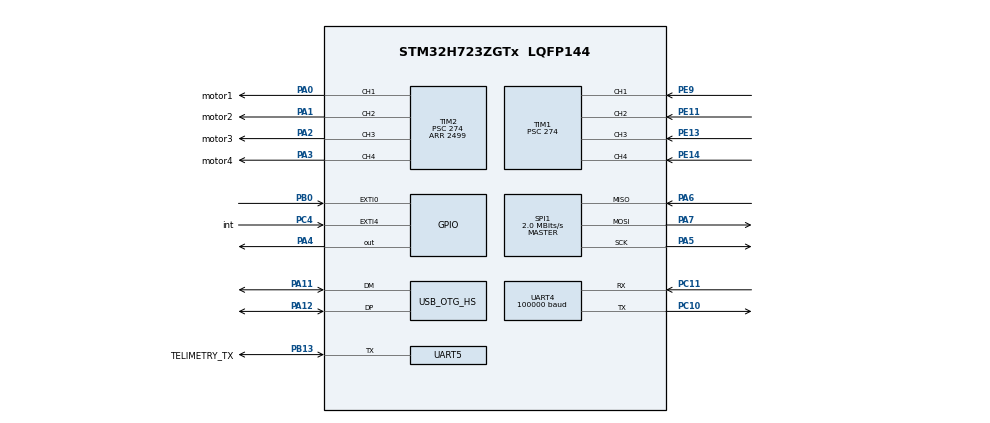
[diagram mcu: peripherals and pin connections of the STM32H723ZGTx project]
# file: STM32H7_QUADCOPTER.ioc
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CORTEX_M7.default_mode_Activation=1
Dma.Request0=UART4_RX
Dma.UART4_RX.0.Direction=DMA_PERIPH_TO_MEMORY
Dma.UART4_RX.0.EventEnable=DISABLE
Dma.UART4_RX.0.FIFOMode=DMA_FIFOMODE_DISABLE
Dma.UART4_RX.0.Instance=DMA1_Stream0
Dma.UART4_RX.0.MemDataAlignment=DMA_MDATAALIGN_BYTE
Dma.UART4_RX.0.MemInc=DMA_MINC_ENABLE
Dma.UART4_RX.0.Mode=DMA_CIRCULAR
Dma.UART4_RX.0.PeriphDataAlignment=DMA_PDATAALIGN_BYTE
Dma.UART4_RX.0.PeriphInc=DMA_PINC_DISABLE
Dma.UART4_RX.0.Polarity=HAL_DMAMUX_REQ_GEN_RISING
Dma.UART4_RX.0.Priority=DMA_PRIORITY_LOW
Dma.UART4_RX.0.RequestNumber=1
Dma.UART4_RX.0.SignalID=NONE
Dma.UART4_RX.0.SyncEnable=DISABLE
Dma.UART4_RX.0.SyncPolarity=HAL_DMAMUX_SYNC_NO_EVENT
Dma.UART4_RX.0.SyncRequestNumber=1
Dma.UART4_RX.0.SyncSignalID=NONE
Mcu.Family=STM32H7
Mcu.Name=STM32H723ZGTx
Mcu.Package=LQFP144
NVIC.DMA1_Stream0_IRQn=true\:0\:0\:false\:false\:true\:false\:true\:true
NVIC.EXTI0_IRQn=true\:0\:0\:false\:false\:true\:true\:true\:true
NVIC.EXTI4_IRQn=true\:0\:0\:false\:false\:true\:true\:true\:true
NVIC.OTG_HS_IRQn=true\:0\:0\:false\:false\:true\:false\:true\:true
NVIC.PriorityGroup=NVIC_PRIORITYGROUP_4
NVIC.TIM1_CC_IRQn=true\:0\:0\:false\:false\:true\:true\:true\:true
NVIC.UART4_IRQn=true\:0\:0\:false\:false\:true\:true\:true\:true
NVIC.UART5_IRQn=true\:0\:0\:false\:false\:true\:true\:true\:true
PA0.GPIO_Label=motor1
PA0.GPIO_PuPd=GPIO_PULLDOWN
PA0.GPIO_Speed=GPIO_SPEED_FREQ_VERY_HIGH
PA0.Signal=S_TIM2_CH1_ETR
PA1.GPIO_Label=motor2
PA1.GPIO_PuPd=GPIO_PULLDOWN
PA1.GPIO_Speed=GPIO_SPEED_FREQ_VERY_HIGH
PA1.Signal=S_TIM2_CH2
PA11.Mode=Device_Only_FS
PA11.Signal=USB_OTG_HS_DM
PA12.Mode=Device_Only_FS
PA12.Signal=USB_OTG_HS_DP
PA2.GPIO_Label=motor3
PA2.GPIO_PuPd=GPIO_PULLDOWN
PA2.GPIO_Speed=GPIO_SPEED_FREQ_VERY_HIGH
PA2.Signal=S_TIM2_CH3
PA3.GPIO_Label=motor4
PA3.GPIO_PuPd=GPIO_PULLDOWN
PA3.GPIO_Speed=GPIO_SPEED_FREQ_VERY_HIGH
PA3.Signal=S_TIM2_CH4
PA4.GPIO_PuPd=GPIO_PULLUP
PA4.GPIO_Speed=GPIO_SPEED_FREQ_VERY_HIGH
PA4.PinState=GPIO_PIN_SET
PA4.Signal=GPIO_Output
PA5.Mode=Full_Duplex_Master
PA5.Signal=SPI1_SCK
PA6.Mode=Full_Duplex_Master
PA6.Signal=SPI1_MISO
PA7.Mode=Full_Duplex_Master
PA7.Signal=SPI1_MOSI
PB0.Signal=GPXTI0
PB13.GPIO_Label=TELIMETRY_TX
PB13.GPIO_PuPd=GPIO_PULLUP
PB13.GPIO_Speed=GPIO_SPEED_FREQ_HIGH
PB13.Mode=Half_duplex(single_wire_mode)
PB13.Signal=UART5_TX
PC10.Mode=Asynchronous
PC10.Signal=UART4_TX
PC11.GPIO_PuPd=GPIO_PULLUP
PC11.GPIO_Speed=GPIO_SPEED_FREQ_VERY_HIGH
PC11.Mode=Asynchronous
PC11.Signal=UART4_RX
PC4.GPIO_Label=int
PC4.GPIO_PuPd=GPIO_PULLDOWN
PC4.Signal=GPXTI4
PE11.Signal=S_TIM1_CH2
PE13.Signal=S_TIM1_CH3
PE14.Signal=S_TIM1_CH4
PE9.Signal=S_TIM1_CH1
PH0-OSC_IN.Mode=HSE-External-Oscillator
PH0-OSC_IN.Signal=RCC_OSC_IN
PH1-OSC_OUT.Mode=HSE-External-Oscillator
PH1-OSC_OUT.Signal=RCC_OSC_OUT
ProjectManager.HeapSize=0x1000
ProjectManager.StackSize=0x800
ProjectManager.TargetToolchain=STM32CubeIDE
RCC.ADCFreq_Value=50390625
RCC.APB1Freq_Value=137500000
RCC.APB2Freq_Value=137500000
RCC.APB3Freq_Value=137500000
RCC.APB4Freq_Value=137500000
RCC.CortexFreq_Value=550000000
RCC.D1PPRE=RCC_APB3_DIV2
RCC.D2PPRE1=RCC_APB1_DIV2
RCC.D2PPRE2=RCC_APB2_DIV2
RCC.D3PPRE=RCC_APB4_DIV2
RCC.DIVM1=2
RCC.DIVN1=44
RCC.DIVP1=1
RCC.DIVQ1=4
RCC.HCLKFreq_Value=275000000
RCC.HPRE=RCC_HCLK_DIV2
RCC.PLL2FRACN=0
RCC.PLL3FRACN=0
RCC.PLLFRACN=0
RCC.PLLSourceVirtual=RCC_PLLSOURCE_HSE
RCC.SPI123CLockSelection=RCC_SPI123CLKSOURCE_CLKP
RCC.SYSCLKFreq_VALUE=550000000
RCC.SYSCLKSource=RCC_SYSCLKSOURCE_PLLCLK
RCC.USBCLockSelection=RCC_USBCLKSOURCE_HSI48
RCC.USBFreq_Value=48000000
SH.S_TIM1_CH1.0=TIM1_CH1,Input_Capture1_from_TI1
SH.S_TIM1_CH2.0=TIM1_CH2,Input_Capture2_from_TI2
SH.S_TIM1_CH3.0=TIM1_CH3,Input_Capture3_from_TI3
SH.S_TIM1_CH4.0=TIM1_CH4,Input_Capture4_from_TI4
SH.S_TIM2_CH1_ETR.0=TIM2_CH1,PWM Generation1 CH1
SH.S_TIM2_CH2.0=TIM2_CH2,PWM Generation2 CH2
SH.S_TIM2_CH3.0=TIM2_CH3,PWM Generation3 CH3
SH.S_TIM2_CH4.0=TIM2_CH4,PWM Generation4 CH4
SPI1.BaudRatePrescaler=SPI_BAUDRATEPRESCALER_32
SPI1.CLKPhase=SPI_PHASE_2EDGE
SPI1.CLKPolarity=SPI_POLARITY_HIGH
SPI1.CalculateBaudRate=2.0 MBits/s
SPI1.DataSize=SPI_DATASIZE_8BIT
SPI1.Direction=SPI_DIRECTION_2LINES
SPI1.FifoThreshold=SPI_FIFO_THRESHOLD_04DATA
SPI1.Mode=SPI_MODE_MASTER
SPI1.NSSPMode=SPI_NSS_PULSE_DISABLE
SPI1.VirtualType=VM_MASTER
STMicroelectronics.FP-SNS-STAIOTCFT.1.1.0.MathOoLibCcCMSISJjDSPJjInclude=true
STMicroelectronics.FP-SNS-STAIOTCFT.1.1.0.MathOoLibCcCMSISJjDSPJjLib=true
STMicroelectronics.X-CUBE-MEMS1.12.0.0.SensorsJjSTM32IiMotionACIiLibraryJjCore=true
STMicroelectronics.X-CUBE-MEMS1.12.0.0.SensorsJjSTM32IiMotionFXIiLibraryJjCore=true
STMicroelectronics.X-CUBE-MEMS1.12.0.0.SensorsJjSTM32IiMotionGCIiLibraryJjCore=true
TIM1.Channel-Input_Capture1_from_TI1=TIM_CHANNEL_1
TIM1.Channel-Input_Capture2_from_TI2=TIM_CHANNEL_2
TIM1.Channel-Input_Capture3_from_TI3=TIM_CHANNEL_3
TIM1.Channel-Input_Capture4_from_TI4=TIM_CHANNEL_4
TIM1.ICPolarity_CH1=TIM_INPUTCHANNELPOLARITY_RISING
TIM1.Prescaler=274
TIM2.Channel-PWM\ Generation1\ CH1=TIM_CHANNEL_1
TIM2.Channel-PWM\ Generation2\ CH2=TIM_CHANNEL_2
TIM2.Channel-PWM\ Generation3\ CH3=TIM_CHANNEL_3
TIM2.Channel-PWM\ Generation4\ CH4=TIM_CHANNEL_4
TIM2.Period=2499
TIM2.Prescaler=274
UART4.BaudRate=100000
UART4.DataInvertParam=UART_ADVFEATURE_DATAINV_DISABLE
UART4.FIFOMode=FIFOMODE_DISABLE
UART4.Parity=PARITY_EVEN
UART4.RxPinLevelInvertParam=UART_ADVFEATURE_RXINV_ENABLE
UART4.StopBits=UART_STOPBITS_2
UART4.WordLength=WORDLENGTH_9B
UART5.BaudRate=56700
UART5.Mode=MODE_TX_RX
UART5.RxPinLevelInvertParam=UART_ADVFEATURE_RXINV_ENABLE
UART5.TxPinLevelInvertParam=UART_ADVFEATURE_TXINV_ENABLE
USB_DEVICE.CLASS_NAME_HS=CDC
USB_DEVICE.VirtualMode=Cdc
USB_DEVICE.VirtualModeHS=Cdc_HS
USB_OTG_HS.VirtualMode-Device_Only_FS=Device_Only_FS
VP_CRC_VS_CRC.Mode=CRC_Activate
VP_MEMORYMAP_VS_MEMORYMAP.Mode=CurAppReg
VP_STMicroelectronics.FP-SNS-STAIOTCFT_VS_CMSISJjMathOoLib_1.0.0_1.1.0.Mode=CMSISJjMathOoLib
VP_STMicroelectronics.X-CUBE-MEMS1_VS_SensorsJjSTM32IiMotionACIiLibrary_2.6.2_12.0.0.Mode=SensorsJjSTM32IiMotionACIiLibrary
VP_STMicroelectronics.X-CUBE-MEMS1_VS_SensorsJjSTM32IiMotionFXIiLibrary_2.10.0_12.0.0.Mode=SensorsJjSTM32IiMotionFXIiLibrary
VP_STMicroelectronics.X-CUBE-MEMS1_VS_SensorsJjSTM32IiMotionGCIiLibrary_2.7.0_12.0.0.Mode=SensorsJjSTM32IiMotionGCIiLibrary
VP_TIM1_VS_ClockSourceINT.Mode=Internal
VP_TIM2_VS_ClockSourceINT.Mode=Internal
VP_USB_DEVICE_VS_USB_DEVICE_CDC_HS.Mode=CDC_HS
board=custom

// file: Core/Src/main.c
#include "main.h"
#include "usb_device.h"
#include "motion_ac_manager.h"
/* USER CODE BEGIN Includes */
#include <stdio.h>
#include "motors.h"
#include "pid_control.h"
#include "radio.h"
#include "lsm6ds3.h"
#include "print.h"
#include "flight_control.h"
#include "sensor_fusion.h"
#include <stdbool.h>
#include "gyro_calibration.h"
#include "telemetry.h"
#include "barometer.h"
/* USER CODE END Includes */

/* USER CODE BEGIN PTD */
extern volatile receiver_t radio;
extern uint8_t buffer[256];
extern uint16_t size;
extern volatile IMU_Data_t sensor_data;
uint8_t sbus_buffer[25] __attribute__((section(".RAM_D2")));
extern uint16_t sbus_channels[16];
extern uint8_t failsafe_status;
extern float roll_cmd;
extern float pitch_cmd;
extern float yaw_cmd;
/* USER CODE END PTD */

/* USER CODE BEGIN PD */
#define TELIMETRY

/* USER CODE END PD */

/* USER CODE BEGIN PM */
/* Private variables ---------------------------------------------------------*/

/* USER CODE END PM */

CRC_HandleTypeDef hcrc;

SPI_HandleTypeDef hspi1;

TIM_HandleTypeDef htim1;
TIM_HandleTypeDef htim2;

UART_HandleTypeDef huart4;
UART_HandleTypeDef huart5;
DMA_HandleTypeDef hdma_uart4_rx;

void SystemClock_Config(void);
void PeriphCommonClock_Config(void);
static void MPU_Config(void);
static void MX_GPIO_Init(void);
static void MX_DMA_Init(void);
static void MX_SPI1_Init(void);
static void MX_TIM1_Init(void);
static void MX_TIM2_Init(void);
static void MX_CRC_Init(void);
static void MX_UART4_Init(void);
static void MX_UART5_Init(void);
/* USER CODE BEGIN PFP */
uint8_t USB_transmit_buffer[256];
uint16_t transmit_size = 0;
volatile uint8_t esc_calibration;
#define MFX_STATE_SIZE 2432 // Check documentation for your specific version
#define MGC_STATE_SIZE 2432 // Check documentation for your specific version
#define MAC_STATE_SIZE 2432 // Check documentation for your specific version

uint8_t mfx_state[MFX_STATE_SIZE] __attribute__((section(".dtcmram")));
uint8_t mgc_state[MGC_STATE_SIZE] __attribute__((section(".dtcmram")));
uint8_t mac_state[MAC_STATE_SIZE] __attribute__((section(".dtcmram")));
extern bool motor_test;
uint8_t rx_byte;
void loop_processing(void);

/* USER CODE END PFP */

int main(void) {

	/* MPU Configuration--------------------------------------------------------*/
	MPU_Config();

	/* MCU Configuration--------------------------------------------------------*/

	/* Reset of all peripherals, Initializes the Flash interface and the Systick. */
	HAL_Init();

	/* Configure the system clock */
	SystemClock_Config();

	/* Configure the peripherals common clocks */
	PeriphCommonClock_Config();

	/* USER CODE BEGIN SysInit */
	// 1. Enable the Instruction Cache (Safe to just enable)
	SCB_EnableICache();

	// 2. CRITICAL: Invalidate the Data Cache FIRST to clear power-up garbage tags.
	// Do NOT call a "Clean" or "CleanInvalidate" function here!
	SCB_InvalidateDCache();

	// 3. Now it is safe to enable the Data Cache
	SCB_EnableDCache();
	/* USER CODE END SysInit */
	/* USER CODE BEGIN Init */

	MX_GPIO_Init();
	MX_DMA_Init();
	MX_SPI1_Init();
	MX_TIM1_Init();
	MX_TIM2_Init();
	MX_USB_DEVICE_Init();
	MX_CRC_Init();
	MX_UART5_Init();
	MS5611_Init();
	/* USER CODE END Init */

#ifdef TRADITIONAL_RECEIVER
  	MX_TIM1_Init();

  	HAL_TIM_IC_Start_IT(&htim1, TIM_CHANNEL_1); // PE9
  	HAL_TIM_IC_Start_IT(&htim1, TIM_CHANNEL_2); // PE11
  	HAL_TIM_IC_Start_IT(&htim1, TIM_CHANNEL_3); // PE13
  	HAL_TIM_IC_Start_IT(&htim1, TIM_CHANNEL_4); // PE14

  #endif

	IMU_Init();
	MotionAC_manager_init(1);

	// Enable the Interrupt Line 4 (PC4 uses EXTI4)
	HAL_NVIC_SetPriority(EXTI4_IRQn, 1, 0);
	HAL_NVIC_EnableIRQ(EXTI4_IRQn);

	HAL_TIM_PWM_Start(&htim2, TIM_CHANNEL_1);
	HAL_TIM_PWM_Start(&htim2, TIM_CHANNEL_2);
	HAL_TIM_PWM_Start(&htim2, TIM_CHANNEL_3);
	HAL_TIM_PWM_Start(&htim2, TIM_CHANNEL_4);
	/* Start the first receive manually to kickstart the interrupt chain */
	update_motors(ONESHOT125_MIN, ONESHOT125_MIN, ONESHOT125_MIN,
			ONESHOT125_MIN);
	/* Disable Caches for debugging library linking */

#ifdef SBUS_RECEIVER
	MX_UART4_Init();

	HAL_UART_Receive_DMA(&huart4, sbus_buffer, 25);
	__HAL_UART_ENABLE_IT(&huart4, UART_IT_IDLE); // Enable the IDLE line interrupt
#endif

#ifdef TELIMETRY
	//	 HAL_UART_Receive_IT(&huart5, &rx_byte, 1);
#endif
	/* Infinite loop */
	/* USER CODE BEGIN WHILE */

	while (1) {

		loop_processing();

		/* USER CODE END WHILE */

	}
}

void SystemClock_Config(void) {
	RCC_OscInitTypeDef RCC_OscInitStruct = { 0 };
	RCC_ClkInitTypeDef RCC_ClkInitStruct = { 0 };

	/** Supply configuration update enable
	 */
	HAL_PWREx_ConfigSupply(PWR_LDO_SUPPLY);

	/** Configure the main internal regulator output voltage
	 */
	__HAL_PWR_VOLTAGESCALING_CONFIG(PWR_REGULATOR_VOLTAGE_SCALE0);

	while (!__HAL_PWR_GET_FLAG(PWR_FLAG_VOSRDY)) {
	}

	/** Initializes the RCC Oscillators according to the specified parameters
	 * in the RCC_OscInitTypeDef structure.
	 */
	RCC_OscInitStruct.OscillatorType = RCC_OSCILLATORTYPE_HSI48
			| RCC_OSCILLATORTYPE_HSI | RCC_OSCILLATORTYPE_HSE;
	RCC_OscInitStruct.HSEState = RCC_HSE_ON;
	RCC_OscInitStruct.HSIState = RCC_HSI_DIV1;
	RCC_OscInitStruct.HSICalibrationValue = 64;
	RCC_OscInitStruct.HSI48State = RCC_HSI48_ON;
	RCC_OscInitStruct.PLL.PLLState = RCC_PLL_ON;
	RCC_OscInitStruct.PLL.PLLSource = RCC_PLLSOURCE_HSE;
	RCC_OscInitStruct.PLL.PLLM = 2;
	RCC_OscInitStruct.PLL.PLLN = 44;
	RCC_OscInitStruct.PLL.PLLP = 1;
	RCC_OscInitStruct.PLL.PLLQ = 4;
	RCC_OscInitStruct.PLL.PLLR = 2;
	RCC_OscInitStruct.PLL.PLLRGE = RCC_PLL1VCIRANGE_3;
	RCC_OscInitStruct.PLL.PLLVCOSEL = RCC_PLL1VCOWIDE;
	RCC_OscInitStruct.PLL.PLLFRACN = 0;
	if (HAL_RCC_OscConfig(&RCC_OscInitStruct) != HAL_OK) {
		Error_Handler();
	}

	/** Initializes the CPU, AHB and APB buses clocks
	 */
	RCC_ClkInitStruct.ClockType = RCC_CLOCKTYPE_HCLK | RCC_CLOCKTYPE_SYSCLK
			| RCC_CLOCKTYPE_PCLK1 | RCC_CLOCKTYPE_PCLK2 | RCC_CLOCKTYPE_D3PCLK1
			| RCC_CLOCKTYPE_D1PCLK1;
	RCC_ClkInitStruct.SYSCLKSource = RCC_SYSCLKSOURCE_PLLCLK;
	RCC_ClkInitStruct.SYSCLKDivider = RCC_SYSCLK_DIV1;
	RCC_ClkInitStruct.AHBCLKDivider = RCC_HCLK_DIV2;
	RCC_ClkInitStruct.APB3CLKDivider = RCC_APB3_DIV2;
	RCC_ClkInitStruct.APB1CLKDivider = RCC_APB1_DIV2;
	RCC_ClkInitStruct.APB2CLKDivider = RCC_APB2_DIV2;
	RCC_ClkInitStruct.APB4CLKDivider = RCC_APB4_DIV2;

	if (HAL_RCC_ClockConfig(&RCC_ClkInitStruct, FLASH_LATENCY_3) != HAL_OK) {
		Error_Handler();
	}
}

void PeriphCommonClock_Config(void) {
	RCC_PeriphCLKInitTypeDef PeriphClkInitStruct = { 0 };

	/** Initializes the peripherals clock
	 */
	PeriphClkInitStruct.PeriphClockSelection = RCC_PERIPHCLK_CKPER;
	PeriphClkInitStruct.CkperClockSelection = RCC_CLKPSOURCE_HSI;
	if (HAL_RCCEx_PeriphCLKConfig(&PeriphClkInitStruct) != HAL_OK) {
		Error_Handler();
	}
}

static void MX_CRC_Init(void) {

	hcrc.Instance = CRC;
	hcrc.Init.DefaultPolynomialUse = DEFAULT_POLYNOMIAL_ENABLE;
	hcrc.Init.DefaultInitValueUse = DEFAULT_INIT_VALUE_ENABLE;
	hcrc.Init.InputDataInversionMode = CRC_INPUTDATA_INVERSION_NONE;
	hcrc.Init.OutputDataInversionMode = CRC_OUTPUTDATA_INVERSION_DISABLE;
	hcrc.InputDataFormat = CRC_INPUTDATA_FORMAT_BYTES;
	if (HAL_CRC_Init(&hcrc) != HAL_OK) {
		Error_Handler();
	}

}

static void MX_SPI1_Init(void) {

	/* SPI1 parameter configuration*/
	hspi1.Instance = SPI1;
	hspi1.Init.Mode = SPI_MODE_MASTER;
	hspi1.Init.Direction = SPI_DIRECTION_2LINES;
	hspi1.Init.DataSize = SPI_DATASIZE_8BIT;
	hspi1.Init.CLKPolarity = SPI_POLARITY_HIGH;
	hspi1.Init.CLKPhase = SPI_PHASE_2EDGE;
	hspi1.Init.NSS = SPI_NSS_SOFT;
	hspi1.Init.BaudRatePrescaler = SPI_BAUDRATEPRESCALER_32;
	hspi1.Init.FirstBit = SPI_FIRSTBIT_MSB;
	hspi1.Init.TIMode = SPI_TIMODE_DISABLE;
	hspi1.Init.CRCCalculation = SPI_CRCCALCULATION_DISABLE;
	hspi1.Init.CRCPolynomial = 0x0;
	hspi1.Init.NSSPMode = SPI_NSS_PULSE_DISABLE;
	hspi1.Init.NSSPolarity = SPI_NSS_POLARITY_LOW;
	hspi1.Init.FifoThreshold = SPI_FIFO_THRESHOLD_01DATA;
	hspi1.Init.TxCRCInitializationPattern =
			SPI_CRC_INITIALIZATION_ALL_ZERO_PATTERN;
	hspi1.Init.RxCRCInitializationPattern =
			SPI_CRC_INITIALIZATION_ALL_ZERO_PATTERN;
	hspi1.Init.MasterSSIdleness = SPI_MASTER_SS_IDLENESS_00CYCLE;
	hspi1.Init.MasterInterDataIdleness = SPI_MASTER_INTERDATA_IDLENESS_00CYCLE;
	hspi1.Init.MasterReceiverAutoSusp = SPI_MASTER_RX_AUTOSUSP_DISABLE;
	hspi1.Init.MasterKeepIOState = SPI_MASTER_KEEP_IO_STATE_DISABLE;
	hspi1.Init.IOSwap = SPI_IO_SWAP_DISABLE;
	if (HAL_SPI_Init(&hspi1) != HAL_OK) {
		Error_Handler();
	}

}

static void MX_TIM1_Init(void) {

	TIM_ClockConfigTypeDef sClockSourceConfig = { 0 };
	TIM_MasterConfigTypeDef sMasterConfig = { 0 };
	TIM_IC_InitTypeDef sConfigIC = { 0 };

	htim1.Instance = TIM1;
	htim1.Init.Prescaler = 274;
	htim1.Init.CounterMode = TIM_COUNTERMODE_UP;
	htim1.Init.Period = 65535;
	htim1.Init.ClockDivision = TIM_CLOCKDIVISION_DIV1;
	htim1.Init.RepetitionCounter = 0;
	htim1.Init.AutoReloadPreload = TIM_AUTORELOAD_PRELOAD_DISABLE;
	if (HAL_TIM_Base_Init(&htim1) != HAL_OK) {
		Error_Handler();
	}
	sClockSourceConfig.ClockSource = TIM_CLOCKSOURCE_INTERNAL;
	if (HAL_TIM_ConfigClockSource(&htim1, &sClockSourceConfig) != HAL_OK) {
		Error_Handler();
	}
	if (HAL_TIM_IC_Init(&htim1) != HAL_OK) {
		Error_Handler();
	}
	sMasterConfig.MasterOutputTrigger = TIM_TRGO_RESET;
	sMasterConfig.MasterOutputTrigger2 = TIM_TRGO2_RESET;
	sMasterConfig.MasterSlaveMode = TIM_MASTERSLAVEMODE_DISABLE;
	if (HAL_TIMEx_MasterConfigSynchronization(&htim1, &sMasterConfig)
			!= HAL_OK) {
		Error_Handler();
	}
	sConfigIC.ICPolarity = TIM_INPUTCHANNELPOLARITY_RISING;
	sConfigIC.ICSelection = TIM_ICSELECTION_DIRECTTI;
	sConfigIC.ICPrescaler = TIM_ICPSC_DIV1;
	sConfigIC.ICFilter = 0;
	if (HAL_TIM_IC_ConfigChannel(&htim1, &sConfigIC, TIM_CHANNEL_1) != HAL_OK) {
		Error_Handler();
	}
	if (HAL_TIM_IC_ConfigChannel(&htim1, &sConfigIC, TIM_CHANNEL_2) != HAL_OK) {
		Error_Handler();
	}
	if (HAL_TIM_IC_ConfigChannel(&htim1, &sConfigIC, TIM_CHANNEL_3) != HAL_OK) {
		Error_Handler();
	}
	if (HAL_TIM_IC_ConfigChannel(&htim1, &sConfigIC, TIM_CHANNEL_4) != HAL_OK) {
		Error_Handler();
	}

}
static void MX_TIM2_Init(void) {
	TIM_ClockConfigTypeDef sClockSourceConfig = { 0 };
	TIM_MasterConfigTypeDef sMasterConfig = { 0 };
	TIM_OC_InitTypeDef sConfigOC = { 0 };

	htim2.Instance = TIM2;

	// Hardened Oneshot125 Configuration:
	// Prescaler = 0 splits no clocks, running TIM2 at the full 275 MHz speed.
	// 1 tick = ~3.636 nanoseconds for incredible signal tracking precision.
	htim2.Init.Prescaler = 0;
	htim2.Init.CounterMode = TIM_COUNTERMODE_UP;

	// Counter Period (ARR) = 165000 ticks.
	// At 275 MHz, counting to 165000 takes exactly 600 microseconds (Matches your 1666Hz flight loop).
	htim2.Init.Period = 165000;

	htim2.Init.ClockDivision = TIM_CLOCKDIVISION_DIV1;
	htim2.Init.AutoReloadPreload = TIM_AUTORELOAD_PRELOAD_DISABLE;
	if (HAL_TIM_Base_Init(&htim2) != HAL_OK) {
		Error_Handler();
	}
	sClockSourceConfig.ClockSource = TIM_CLOCKSOURCE_INTERNAL;
	if (HAL_TIM_ConfigClockSource(&htim2, &sClockSourceConfig) != HAL_OK) {
		Error_Handler();
	}
	if (HAL_TIM_PWM_Init(&htim2) != HAL_OK) {
		Error_Handler();
	}
	sMasterConfig.MasterOutputTrigger = TIM_TRGO_RESET;
	sMasterConfig.MasterSlaveMode = TIM_MASTERSLAVEMODE_DISABLE;
	if (HAL_TIMEx_MasterConfigSynchronization(&htim2, &sMasterConfig)
			!= HAL_OK) {
		Error_Handler();
	}
	sConfigOC.OCMode = TIM_OCMODE_PWM1;
	sConfigOC.Pulse = 0;
	sConfigOC.OCPolarity = TIM_OCPOLARITY_HIGH;
	sConfigOC.OCFastMode = TIM_OCFAST_DISABLE;
	if (HAL_TIM_PWM_ConfigChannel(&htim2, &sConfigOC, TIM_CHANNEL_1)
			!= HAL_OK) {
		Error_Handler();
	}
	if (HAL_TIM_PWM_ConfigChannel(&htim2, &sConfigOC, TIM_CHANNEL_2)
			!= HAL_OK) {
		Error_Handler();
	}
	if (HAL_TIM_PWM_ConfigChannel(&htim2, &sConfigOC, TIM_CHANNEL_3)
			!= HAL_OK) {
		Error_Handler();
	}
	if (HAL_TIM_PWM_ConfigChannel(&htim2, &sConfigOC, TIM_CHANNEL_4)
			!= HAL_OK) {
		Error_Handler();
	}
	HAL_TIM_MspPostInit(&htim2);
}

//static void MX_TIM2_Init(void)
//{
//
//  /* USER CODE BEGIN TIM2_Init 0 */
//
//  /* USER CODE END TIM2_Init 0 */
//
//  TIM_ClockConfigTypeDef sClockSourceConfig = {0};
//  TIM_MasterConfigTypeDef sMasterConfig = {0};
//  TIM_OC_InitTypeDef sConfigOC = {0};
//
//  /* USER CODE BEGIN TIM2_Init 1 */
//
//  /* USER CODE END TIM2_Init 1 */
//  htim2.Instance = TIM2;
//  htim2.Init.Prescaler = 274;
//  htim2.Init.CounterMode = TIM_COUNTERMODE_UP;
//  htim2.Init.Period = 2499;
//  htim2.Init.ClockDivision = TIM_CLOCKDIVISION_DIV1;
//  htim2.Init.AutoReloadPreload = TIM_AUTORELOAD_PRELOAD_DISABLE;
//  if (HAL_TIM_Base_Init(&htim2) != HAL_OK)
//  {
//    Error_Handler();
//  }
//  sClockSourceConfig.ClockSource = TIM_CLOCKSOURCE_INTERNAL;
//  if (HAL_TIM_ConfigClockSource(&htim2, &sClockSourceConfig) != HAL_OK)
//  {
//    Error_Handler();
//  }
//  if (HAL_TIM_PWM_Init(&htim2) != HAL_OK)
//  {
//    Error_Handler();
//  }
//  sMasterConfig.MasterOutputTrigger = TIM_TRGO_RESET;
//  sMasterConfig.MasterSlaveMode = TIM_MASTERSLAVEMODE_DISABLE;
//  if (HAL_TIMEx_MasterConfigSynchronization(&htim2, &sMasterConfig) != HAL_OK)
//  {
//    Error_Handler();
//  }
//  sConfigOC.OCMode = TIM_OCMODE_PWM1;
//  sConfigOC.Pulse = 0;
//  sConfigOC.OCPolarity = TIM_OCPOLARITY_HIGH;
//  sConfigOC.OCFastMode = TIM_OCFAST_DISABLE;
//  if (HAL_TIM_PWM_ConfigChannel(&htim2, &sConfigOC, TIM_CHANNEL_1) != HAL_OK)
//  {
//    Error_Handler();
//  }
//  if (HAL_TIM_PWM_ConfigChannel(&htim2, &sConfigOC, TIM_CHANNEL_2) != HAL_OK)
//  {
//    Error_Handler();
//  }
//  if (HAL_TIM_PWM_ConfigChannel(&htim2, &sConfigOC, TIM_CHANNEL_3) != HAL_OK)
//  {
//    Error_Handler();
//  }
//  if (HAL_TIM_PWM_ConfigChannel(&htim2, &sConfigOC, TIM_CHANNEL_4) != HAL_OK)
//  {
//    Error_Handler();
//  }
//  /* USER CODE BEGIN TIM2_Init 2 */
//
//  /* USER CODE END TIM2_Init 2 */
//  HAL_TIM_MspPostInit(&htim2);
//
//}
static void MX_UART4_Init(void) {

	huart4.Instance = UART4;
	huart4.Init.BaudRate = 100000;
	huart4.Init.WordLength = UART_WORDLENGTH_9B;
	huart4.Init.StopBits = UART_STOPBITS_2;
	huart4.Init.Parity = UART_PARITY_EVEN;
	huart4.Init.Mode = UART_MODE_TX_RX;
	huart4.Init.HwFlowCtl = UART_HWCONTROL_NONE;
	huart4.Init.OverSampling = UART_OVERSAMPLING_16;
	huart4.Init.OneBitSampling = UART_ONE_BIT_SAMPLE_DISABLE;
	huart4.Init.ClockPrescaler = UART_PRESCALER_DIV1;
	huart4.AdvancedInit.AdvFeatureInit = UART_ADVFEATURE_RXINVERT_INIT;
	huart4.AdvancedInit.RxPinLevelInvert = UART_ADVFEATURE_RXINV_ENABLE;
	if (HAL_UART_Init(&huart4) != HAL_OK) {
		Error_Handler();
	}
	if (HAL_UARTEx_SetTxFifoThreshold(&huart4, UART_TXFIFO_THRESHOLD_1_8)
			!= HAL_OK) {
		Error_Handler();
	}
	if (HAL_UARTEx_SetRxFifoThreshold(&huart4, UART_RXFIFO_THRESHOLD_1_8)
			!= HAL_OK) {
		Error_Handler();
	}
	if (HAL_UARTEx_DisableFifoMode(&huart4) != HAL_OK) {
		Error_Handler();
	}

}

static void MX_UART5_Init(void) {

	huart5.Instance = UART5;
	huart5.Init.BaudRate = 56700;
	huart5.Init.WordLength = UART_WORDLENGTH_8B;
	huart5.Init.StopBits = UART_STOPBITS_1;
	huart5.Init.Parity = UART_PARITY_NONE;
	huart5.Init.Mode = UART_MODE_TX_RX;
	huart5.Init.HwFlowCtl = UART_HWCONTROL_NONE;
	huart5.Init.OverSampling = UART_OVERSAMPLING_16;
	huart5.Init.OneBitSampling = UART_ONE_BIT_SAMPLE_DISABLE;
	huart5.Init.ClockPrescaler = UART_PRESCALER_DIV1;
	huart5.AdvancedInit.AdvFeatureInit = UART_ADVFEATURE_TXINVERT_INIT
			| UART_ADVFEATURE_RXINVERT_INIT;
	huart5.AdvancedInit.TxPinLevelInvert = UART_ADVFEATURE_TXINV_ENABLE;
	huart5.AdvancedInit.RxPinLevelInvert = UART_ADVFEATURE_RXINV_ENABLE;
	if (HAL_HalfDuplex_Init(&huart5) != HAL_OK) {
		Error_Handler();
	}
	if (HAL_UARTEx_SetTxFifoThreshold(&huart5, UART_TXFIFO_THRESHOLD_1_8)
			!= HAL_OK) {
		Error_Handler();
	}
	if (HAL_UARTEx_SetRxFifoThreshold(&huart5, UART_RXFIFO_THRESHOLD_1_8)
			!= HAL_OK) {
		Error_Handler();
	}
	if (HAL_UARTEx_DisableFifoMode(&huart5) != HAL_OK) {
		Error_Handler();
	}

}

static void MX_DMA_Init(void) {

	/* DMA controller clock enable */
	__HAL_RCC_DMA1_CLK_ENABLE();

	/* DMA interrupt init */
	/* DMA1_Stream0_IRQn interrupt configuration */
	HAL_NVIC_SetPriority(DMA1_Stream0_IRQn, 0, 0);
	HAL_NVIC_EnableIRQ(DMA1_Stream0_IRQn);

}

static void MX_GPIO_Init(void) {
	GPIO_InitTypeDef GPIO_InitStruct = { 0 };

	/* GPIO Ports Clock Enable */
	__HAL_RCC_GPIOH_CLK_ENABLE();
	__HAL_RCC_GPIOA_CLK_ENABLE();
	__HAL_RCC_GPIOC_CLK_ENABLE();
	__HAL_RCC_GPIOB_CLK_ENABLE();
	__HAL_RCC_GPIOE_CLK_ENABLE();

//
//	/*Configure GPIO pin : PB0 */
//	GPIO_InitStruct.Pin = GPIO_PIN_0;
//	GPIO_InitStruct.Mode = GPIO_MODE_IT_RISING;
//	GPIO_InitStruct.Pull = GPIO_NOPULL;
//	HAL_GPIO_Init(GPIOB, &GPIO_InitStruct);

	/*Configure GPIO pin : PA4 */
	GPIO_InitStruct.Pin = GPIO_PIN_4 | GPIO_PIN_9;
	GPIO_InitStruct.Mode = GPIO_MODE_OUTPUT_PP;
	GPIO_InitStruct.Pull = GPIO_PULLUP;
	GPIO_InitStruct.Speed = GPIO_SPEED_FREQ_VERY_HIGH;
	HAL_GPIO_Init(GPIOA, &GPIO_InitStruct);

	/*Configure GPIO pin Output Level */
	HAL_GPIO_WritePin(GPIOA, GPIO_PIN_4, GPIO_PIN_SET);
	HAL_GPIO_WritePin(GPIOA, GPIO_PIN_9, GPIO_PIN_SET);

	/*Configure GPIO pin : int_Pin */
	GPIO_InitStruct.Pin = GPIO_PIN_4;
	GPIO_InitStruct.Mode = GPIO_MODE_IT_RISING;
	GPIO_InitStruct.Pull = GPIO_PULLDOWN;
	HAL_GPIO_Init(GPIOC, &GPIO_InitStruct);

//
//	/* EXTI interrupt init*/
	HAL_NVIC_SetPriority(EXTI0_IRQn, 0, 0);
	HAL_NVIC_EnableIRQ(EXTI0_IRQn);

	HAL_NVIC_SetPriority(int_EXTI_IRQn, 0, 0);
	HAL_NVIC_EnableIRQ(int_EXTI_IRQn);

}

/* USER CODE BEGIN 4 */
void loop_processing(void) {

	static uint32_t current, old;
	current = HAL_GetTick();
	if (current - old > 1) {
		old = current;
#define LOG_GYRO
#ifdef LOG_GYRO

//
//				uint8_t size = sprintf((char*) buffer, "\r\n%f,%f,%f",
//						sensor_data.gyro_x,sensor_data.x,
//						sensor_data.gyro_y,
//						sensor_data.gyro_z
//				);
//				usb_print(buffer, size);
//
//			uint8_t size = sprintf((char*) buffer, "\r\n%f,%f,%f,%f,%f,%f",
//							sensor_data.gyro_x,
//							sensor_data.gyro_y,
//							sensor_data.gyro_z,
//							sensor_data.gyro_cal_x,
//							sensor_data.gyro_cal_y,
//							sensor_data.gyro_cal_z);
//			usb_print(buffer, size);

#endif

#ifdef LOG_PID_GAINS

			uint8_t size = sprintf((char*) buffer, "\r\n%f,%f,%f,%f,%f,%f",
						fc.roll.kp,fc.roll.ki,fc.roll.kd,fc.pitch.kp,fc.pitch.ki,fc.pitch.kd);

#endif
//#define PID_LOOP_VARIABLES
#ifdef PID_LOOP_VARIABLES

					uint8_t size = sprintf((char*) buffer, "\r\n%f,%f,%f,%f,%f,%f",
							fc.target_roll_rate,fc.target_pitch_rate,fc.target_yaw_rate,fc.roll.output,fc.pitch.output,fc.yaw.output);
#endif
//		usb_print(buffer, size);
	}
//	uint8_t rx_buf[2];
//			HAL_StatusTypeDef status;
//
//			// 1. Look for the 2-byte sequence (0x7E + Physical ID)
//			// We use a short 1ms timeout so it doesn't block your loop if nothing is arriving
//			status = HAL_UART_Receive(&huart5, rx_buf, 2, 1);
//
//			//size = sprintf(buffer,"%x, %x\r\n",rx_buf[0],rx_buf[1]);
//			//usb_print(buffer,size);
//
//			if (status == HAL_OK) {
//				// Respond immediately
//
//				// If the byte following 0x7E is 0x1B, it's our turn
//				if (rx_buf[0] == 0x7e && rx_buf[1] == 0x01b) {
//					// Respond immediately
//					Send_S_Port_Frame_Fast(0x0100, 1260);
//
//				} else {
//
//					// 3. Clean up and Re-enable
//					(void) UART5->RDR;      // Clear the receive register
//					UART5->ICR = 0xFFFFFFFF; // Clear all interrupt/status flags
//					UART5->CR1 |= USART_CR1_RE;
//				}
//			}

	if (esc_calibration) {
		usb_print((uint8_t*) "ESC_CALIBRATION_STARETED\r\n",
				strlen("ESC_CALIBRATION_STARETED\r\n"));

		float throttle_scalar = normalize_radio_throttle(radio.throttle);

		// Map smoothly starting directly from your ARMED_IDLE up to MAX across full stick travel

		float current_throttle = ONESHOT125_MIN
				+ (throttle_scalar * (ONESHOT125_MAX - ONESHOT125_MIN));

		// CRITICAL HARDWARE PROTECTION CLAMP
		// Protects the timer channels against sub-1000us or over-2000us radio channel jitter
		if (current_throttle > (float) ONESHOT125_MAX)
			current_throttle = (float) ONESHOT125_MAX;
		if (current_throttle < (float) ONESHOT125_MIN)
			current_throttle = (float) ONESHOT125_MIN;
		update_motors((uint32_t) current_throttle, (uint32_t) current_throttle,
				(uint32_t) current_throttle, (uint32_t) current_throttle);
	}

}

/* USER CODE END 4 */

/* MPU Configuration */

void MPU_Config(void) {
	MPU_Region_InitTypeDef MPU_InitStruct = { 0 };

	/* Disables the MPU */
	HAL_MPU_Disable();

	/** Initializes and configures the Region and the memory to be protected
	 */
	MPU_InitStruct.Enable = MPU_REGION_ENABLE;
	MPU_InitStruct.Number = MPU_REGION_NUMBER0;
	MPU_InitStruct.BaseAddress = 0x0;
	MPU_InitStruct.Size = MPU_REGION_SIZE_4GB;
	MPU_InitStruct.SubRegionDisable = 0x87;
	MPU_InitStruct.TypeExtField = MPU_TEX_LEVEL0;
	MPU_InitStruct.AccessPermission = MPU_REGION_NO_ACCESS;
	MPU_InitStruct.DisableExec = MPU_INSTRUCTION_ACCESS_DISABLE;
	MPU_InitStruct.IsShareable = MPU_ACCESS_SHAREABLE;
	MPU_InitStruct.IsCacheable = MPU_ACCESS_NOT_CACHEABLE;
	MPU_InitStruct.IsBufferable = MPU_ACCESS_NOT_BUFFERABLE;

	HAL_MPU_ConfigRegion(&MPU_InitStruct);
	/* Enables the MPU */
	HAL_MPU_Enable(MPU_PRIVILEGED_DEFAULT);

}

void Error_Handler(void) {
	__disable_irq();
	while (1) {
	}
}
